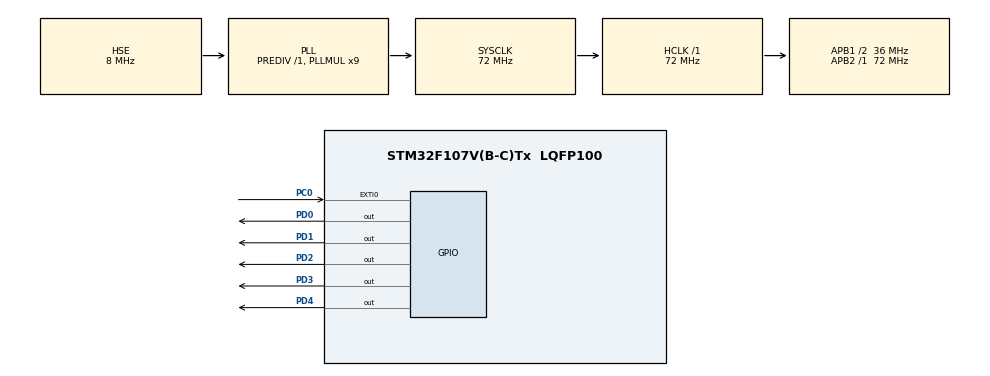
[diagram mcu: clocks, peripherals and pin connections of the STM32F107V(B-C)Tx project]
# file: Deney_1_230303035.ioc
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Mcu.Family=STM32F1
Mcu.Name=STM32F107V(B-C)Tx
Mcu.Package=LQFP100
NVIC.EXTI0_IRQn=true\:0\:0\:false\:false\:true\:true\:true\:true
NVIC.PriorityGroup=NVIC_PRIORITYGROUP_4
OSC_IN.Mode=HSE-External-Oscillator
OSC_IN.Signal=RCC_OSC_IN
OSC_OUT.Mode=HSE-External-Oscillator
OSC_OUT.Signal=RCC_OSC_OUT
PA13.Mode=Serial_Wire
PA13.Signal=SYS_JTMS-SWDIO
PA14.Mode=Serial_Wire
PA14.Signal=SYS_JTCK-SWCLK
PC0.Signal=GPXTI0
PD0.GPIO_Speed=GPIO_SPEED_FREQ_HIGH
PD0.Signal=GPIO_Output
PD1.GPIO_Speed=GPIO_SPEED_FREQ_HIGH
PD1.Signal=GPIO_Output
PD2.GPIO_Speed=GPIO_SPEED_FREQ_HIGH
PD2.Signal=GPIO_Output
PD3.GPIO_Speed=GPIO_SPEED_FREQ_HIGH
PD3.Signal=GPIO_Output
PD4.GPIO_Speed=GPIO_SPEED_FREQ_HIGH
PD4.Signal=GPIO_Output
ProjectManager.HeapSize=0x200
ProjectManager.StackSize=0x400
ProjectManager.TargetToolchain=STM32CubeIDE
RCC.AHBFreq_Value=72000000
RCC.APB1CLKDivider=RCC_HCLK_DIV2
RCC.APB1Freq_Value=36000000
RCC.APB1TimFreq_Value=72000000
RCC.APB2Freq_Value=72000000
RCC.APB2TimFreq_Value=72000000
RCC.HCLKFreq_Value=72000000
RCC.PLLMUL=RCC_PLL_MUL9
RCC.PLLSourceVirtual=RCC_PLLSOURCE_HSE
RCC.SYSCLKFreq_VALUE=72000000
RCC.SYSCLKSource=RCC_SYSCLKSOURCE_PLLCLK
RCC.USBFreq_Value=48000000
board=custom

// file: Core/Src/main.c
/* USER CODE BEGIN Header */
/**
  ******************************************************************************
  * @file           : main.c
  * @brief          : Main program body
  ******************************************************************************
  * @attention
  *
  * Copyright (c) 2026 STMicroelectronics.
  * All rights reserved.
  *
  * This software is licensed under terms that can be found in the LICENSE file
  * in the root directory of this software component.
  * If no LICENSE file comes with this software, it is provided AS-IS.
  *
  ******************************************************************************
  */
/* USER CODE END Header */
#include "main.h"

/* USER CODE BEGIN PV */
	 uint32_t delay = 1000;
/* USER CODE END PV */

void SystemClock_Config(void);
static void MX_GPIO_Init(void);

int main(void)
{

  /* MCU Configuration--------------------------------------------------------*/

  /* Reset of all peripherals, Initializes the Flash interface and the Systick. */
  HAL_Init();

  /* Configure the system clock */
  SystemClock_Config();

  /* Initialize all configured peripherals */
  MX_GPIO_Init();

  /* Infinite loop */
  while (1)
  {
	    HAL_GPIO_WritePin(GPIOD, GPIO_PIN_0, GPIO_PIN_SET);
	    HAL_Delay(delay);
	    HAL_GPIO_WritePin(GPIOD, GPIO_PIN_0, GPIO_PIN_RESET);

	    HAL_GPIO_WritePin(GPIOD, GPIO_PIN_1, GPIO_PIN_SET);
	    HAL_Delay(delay);
	    HAL_GPIO_WritePin(GPIOD, GPIO_PIN_1, GPIO_PIN_RESET);

	    HAL_GPIO_WritePin(GPIOD, GPIO_PIN_2, GPIO_PIN_SET);
	    HAL_Delay(delay);
	    HAL_GPIO_WritePin(GPIOD, GPIO_PIN_2, GPIO_PIN_RESET);

	    HAL_GPIO_WritePin(GPIOD, GPIO_PIN_3, GPIO_PIN_SET);
	    HAL_Delay(delay);
	    HAL_GPIO_WritePin(GPIOD, GPIO_PIN_3, GPIO_PIN_RESET);
  }
}

void SystemClock_Config(void)
{
  RCC_OscInitTypeDef RCC_OscInitStruct = {0};
  RCC_ClkInitTypeDef RCC_ClkInitStruct = {0};

  /** Initializes the RCC Oscillators according to the specified parameters
  * in the RCC_OscInitTypeDef structure.
  */
  RCC_OscInitStruct.OscillatorType = RCC_OSCILLATORTYPE_HSE;
  RCC_OscInitStruct.HSEState = RCC_HSE_ON;
  RCC_OscInitStruct.HSEPredivValue = RCC_HSE_PREDIV_DIV1;
  RCC_OscInitStruct.HSIState = RCC_HSI_ON;
  RCC_OscInitStruct.Prediv1Source = RCC_PREDIV1_SOURCE_HSE;
  RCC_OscInitStruct.PLL.PLLState = RCC_PLL_ON;
  RCC_OscInitStruct.PLL.PLLSource = RCC_PLLSOURCE_HSE;
  RCC_OscInitStruct.PLL.PLLMUL = RCC_PLL_MUL9;
  RCC_OscInitStruct.PLL2.PLL2State = RCC_PLL_NONE;
  if (HAL_RCC_OscConfig(&RCC_OscInitStruct) != HAL_OK)
  {
    Error_Handler();
  }

  /** Initializes the CPU, AHB and APB buses clocks
  */
  RCC_ClkInitStruct.ClockType = RCC_CLOCKTYPE_HCLK|RCC_CLOCKTYPE_SYSCLK
                              |RCC_CLOCKTYPE_PCLK1|RCC_CLOCKTYPE_PCLK2;
  RCC_ClkInitStruct.SYSCLKSource = RCC_SYSCLKSOURCE_PLLCLK;
  RCC_ClkInitStruct.AHBCLKDivider = RCC_SYSCLK_DIV1;
  RCC_ClkInitStruct.APB1CLKDivider = RCC_HCLK_DIV2;
  RCC_ClkInitStruct.APB2CLKDivider = RCC_HCLK_DIV1;

  if (HAL_RCC_ClockConfig(&RCC_ClkInitStruct, FLASH_LATENCY_2) != HAL_OK)
  {
    Error_Handler();
  }

  /** Configure the Systick interrupt time
  */
  __HAL_RCC_PLLI2S_ENABLE();
}

static void MX_GPIO_Init(void)
{
  GPIO_InitTypeDef GPIO_InitStruct = {0};

  /* GPIO Ports Clock Enable */
  __HAL_RCC_GPIOC_CLK_ENABLE();
  __HAL_RCC_GPIOA_CLK_ENABLE();
  __HAL_RCC_GPIOD_CLK_ENABLE();

  /*Configure GPIO pin Output Level */
  HAL_GPIO_WritePin(GPIOD, GPIO_PIN_0|GPIO_PIN_1|GPIO_PIN_2|GPIO_PIN_3, GPIO_PIN_RESET);

  /*Configure GPIO pin : PC0 */
  GPIO_InitStruct.Pin = GPIO_PIN_0;
  GPIO_InitStruct.Mode = GPIO_MODE_IT_RISING;
  GPIO_InitStruct.Pull = GPIO_NOPULL;
  HAL_GPIO_Init(GPIOC, &GPIO_InitStruct);

  /*Configure GPIO pins : PD0 PD1 PD2 PD3 */
  GPIO_InitStruct.Pin = GPIO_PIN_0|GPIO_PIN_1|GPIO_PIN_2|GPIO_PIN_3;
  GPIO_InitStruct.Mode = GPIO_MODE_OUTPUT_PP;
  GPIO_InitStruct.Pull = GPIO_NOPULL;
  GPIO_InitStruct.Speed = GPIO_SPEED_FREQ_HIGH;
  HAL_GPIO_Init(GPIOD, &GPIO_InitStruct);

  /* EXTI interrupt init*/
  HAL_NVIC_SetPriority(EXTI0_IRQn, 0, 0);
  HAL_NVIC_EnableIRQ(EXTI0_IRQn);

}

/* USER CODE BEGIN 4 */
void HAL_GPIO_EXTI_Callback(uint16_t GPIO_Pin)
{

        delay -= 250;
        HAL_GPIO_WritePin(GPIOD, GPIO_PIN_4, GPIO_PIN_SET);
        // HAL_GPIO_TogglePin(GPIOD, GPIO_PIN_4);
         if(delay == 0){
            delay = 1000;
        }

}
/* USER CODE END 4 */

void Error_Handler(void)
{
  __disable_irq();
  while (1)
  {
  }
}
